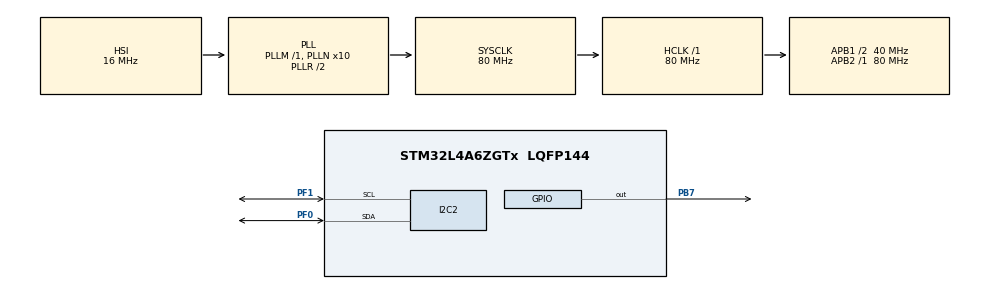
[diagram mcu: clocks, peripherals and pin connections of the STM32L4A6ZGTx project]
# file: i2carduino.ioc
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I2C2.Timing=0x00D09BE3
Mcu.Family=STM32L4
Mcu.Name=STM32L4A6ZGTx
Mcu.Package=LQFP144
NVIC.PriorityGroup=NVIC_PRIORITYGROUP_4
PB7.Signal=GPIO_Output
PF0.Mode=I2C
PF0.Signal=I2C2_SDA
PF1.Mode=I2C
PF1.Signal=I2C2_SCL
ProjectManager.HeapSize=0x200
ProjectManager.StackSize=0x400
ProjectManager.TargetToolchain=STM32CubeIDE
RCC.ADCFreq_Value=192000000
RCC.AHBFreq_Value=80000000
RCC.APB1CLKDivider=RCC_HCLK_DIV2
RCC.APB1Freq_Value=40000000
RCC.APB1TimFreq_Value=80000000
RCC.APB2Freq_Value=80000000
RCC.APB2TimFreq_Value=80000000
RCC.CortexFreq_Value=80000000
RCC.FLatency=FLASH_LATENCY_4
RCC.HCLKFreq_Value=80000000
RCC.HSE_VALUE=8000000
RCC.HSI48_VALUE=48000000
RCC.HSI_VALUE=16000000
RCC.MSI_VALUE=4000000
RCC.PLLN=10
RCC.PLLSAI1N=24
RCC.PLLSourceVirtual=RCC_PLLSOURCE_HSI
RCC.SYSCLKFreq_VALUE=80000000
RCC.SYSCLKSource=RCC_SYSCLKSOURCE_PLLCLK
RCC.USBFreq_Value=192000000
RCC.VCOOutputFreq_Value=160000000
board=NUCLEO-L4A6ZG

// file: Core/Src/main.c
/* USER CODE BEGIN Header */
/**
  ******************************************************************************
  * @file           : main.c
  * @brief          : Main program body
  ******************************************************************************
  * @attention
  *
  * Copyright (c) 2024 STMicroelectronics.
  * All rights reserved.
  *
  * This software is licensed under terms that can be found in the LICENSE file
  * in the root directory of this software component.
  * If no LICENSE file comes with this software, it is provided AS-IS.
  *
  ******************************************************************************
  */
/* USER CODE END Header */
#include "main.h"

I2C_HandleTypeDef hi2c2;

void SystemClock_Config(void);
static void MX_GPIO_Init(void);
static void MX_I2C2_Init(void);
/* USER CODE BEGIN PFP */
int ret;
char dataBuffer[]="Hello my name is Abdur Rehman";

/* USER CODE END PFP */

int main(void)
{

  /* MCU Configuration--------------------------------------------------------*/

  /* Reset of all peripherals, Initializes the Flash interface and the Systick. */
  HAL_Init();

  /* Configure the system clock */
  SystemClock_Config();

  /* Initialize all configured peripherals */
  MX_GPIO_Init();
  MX_I2C2_Init();

  /* Infinite loop */
  /* USER CODE BEGIN WHILE */
  while (1)
  {
	  ret = HAL_I2C_Master_Transmit(&hi2c2,  (4 << 1),(uint8_t *)dataBuffer, 29, 100);
  /* USER CODE END WHILE */
						if ( ret != HAL_OK ) {
						      HAL_GPIO_WritePin(GPIOB,  GPIO_PIN_7, 1);
								 }

						 if ( ret == HAL_OK ) {
							 HAL_GPIO_TogglePin(GPIOB, GPIO_PIN_7);

						HAL_Delay(200);
						 }
		 		HAL_Delay(1000);

}
}

void SystemClock_Config(void)
{
  RCC_OscInitTypeDef RCC_OscInitStruct = {0};
  RCC_ClkInitTypeDef RCC_ClkInitStruct = {0};

  /** Configure the main internal regulator output voltage
  */
  if (HAL_PWREx_ControlVoltageScaling(PWR_REGULATOR_VOLTAGE_SCALE1) != HAL_OK)
  {
    Error_Handler();
  }

  /** Initializes the RCC Oscillators according to the specified parameters
  * in the RCC_OscInitTypeDef structure.
  */
  RCC_OscInitStruct.OscillatorType = RCC_OSCILLATORTYPE_HSI;
  RCC_OscInitStruct.HSIState = RCC_HSI_ON;
  RCC_OscInitStruct.HSICalibrationValue = RCC_HSICALIBRATION_DEFAULT;
  RCC_OscInitStruct.PLL.PLLState = RCC_PLL_ON;
  RCC_OscInitStruct.PLL.PLLSource = RCC_PLLSOURCE_HSI;
  RCC_OscInitStruct.PLL.PLLM = 1;
  RCC_OscInitStruct.PLL.PLLN = 10;
  RCC_OscInitStruct.PLL.PLLP = RCC_PLLP_DIV2;
  RCC_OscInitStruct.PLL.PLLQ = RCC_PLLQ_DIV2;
  RCC_OscInitStruct.PLL.PLLR = RCC_PLLR_DIV2;
  if (HAL_RCC_OscConfig(&RCC_OscInitStruct) != HAL_OK)
  {
    Error_Handler();
  }

  /** Initializes the CPU, AHB and APB buses clocks
  */
  RCC_ClkInitStruct.ClockType = RCC_CLOCKTYPE_HCLK|RCC_CLOCKTYPE_SYSCLK
                              |RCC_CLOCKTYPE_PCLK1|RCC_CLOCKTYPE_PCLK2;
  RCC_ClkInitStruct.SYSCLKSource = RCC_SYSCLKSOURCE_PLLCLK;
  RCC_ClkInitStruct.AHBCLKDivider = RCC_SYSCLK_DIV1;
  RCC_ClkInitStruct.APB1CLKDivider = RCC_HCLK_DIV2;
  RCC_ClkInitStruct.APB2CLKDivider = RCC_HCLK_DIV1;

  if (HAL_RCC_ClockConfig(&RCC_ClkInitStruct, FLASH_LATENCY_4) != HAL_OK)
  {
    Error_Handler();
  }
}

static void MX_I2C2_Init(void)
{

  hi2c2.Instance = I2C2;
  hi2c2.Init.Timing = 0x00D09BE3;
  hi2c2.Init.OwnAddress1 = 0;
  hi2c2.Init.AddressingMode = I2C_ADDRESSINGMODE_7BIT;
  hi2c2.Init.DualAddressMode = I2C_DUALADDRESS_DISABLE;
  hi2c2.Init.OwnAddress2 = 0;
  hi2c2.Init.OwnAddress2Masks = I2C_OA2_NOMASK;
  hi2c2.Init.GeneralCallMode = I2C_GENERALCALL_DISABLE;
  hi2c2.Init.NoStretchMode = I2C_NOSTRETCH_DISABLE;
  if (HAL_I2C_Init(&hi2c2) != HAL_OK)
  {
    Error_Handler();
  }

  /** Configure Analogue filter
  */
  if (HAL_I2CEx_ConfigAnalogFilter(&hi2c2, I2C_ANALOGFILTER_ENABLE) != HAL_OK)
  {
    Error_Handler();
  }

  /** Configure Digital filter
  */
  if (HAL_I2CEx_ConfigDigitalFilter(&hi2c2, 0) != HAL_OK)
  {
    Error_Handler();
  }

}

static void MX_GPIO_Init(void)
{
  GPIO_InitTypeDef GPIO_InitStruct = {0};

  /* GPIO Ports Clock Enable */
  __HAL_RCC_GPIOF_CLK_ENABLE();
  __HAL_RCC_GPIOB_CLK_ENABLE();

  /*Configure GPIO pin Output Level */
  HAL_GPIO_WritePin(GPIOB, GPIO_PIN_7, GPIO_PIN_RESET);

  /*Configure GPIO pin : PB7 */
  GPIO_InitStruct.Pin = GPIO_PIN_7;
  GPIO_InitStruct.Mode = GPIO_MODE_OUTPUT_PP;
  GPIO_InitStruct.Pull = GPIO_NOPULL;
  GPIO_InitStruct.Speed = GPIO_SPEED_FREQ_LOW;
  HAL_GPIO_Init(GPIOB, &GPIO_InitStruct);

}

void Error_Handler(void)
{
  __disable_irq();
  while (1)
  {
  }
}
